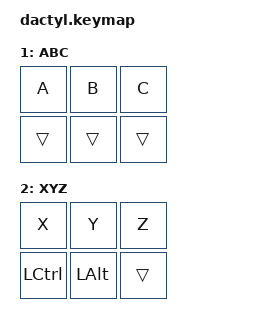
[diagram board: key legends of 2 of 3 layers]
#include <behaviors.dtsi>
#include <dt-bindings/zmk/keys.h>

/ {
       keymap {
        compatible = "zmk,keymap";
		
		
		default_layer { // Layer 0
            display-name = "Base";
// ----------------------------------------------
// |  Q  |   W   |   E   |  R   |  T   |                 
// |  A  |   S   |   D   |  F   |  G   |                 
// |  Z  |   X   |   C   |  V   |  B   |                  
//       |  ALT  |  GUI  |  1   |  2   |3  |  4  |			
//                                     |  5  |  6  | 
            bindings = <
                &kp Q   &kp W   &kp E   &kp R   &kp T  
                &kp A   &kp S   &kp D   &kp F   &kp G  
                &kp Z   &kp X   &kp C   &kp V   &kp B 
                        &kp ALT	&kp GUI	&kp 1   &kp 2   &kp 3   &kp 4
                                                        &kp 5   &kp 6
            >;
        };
		
		
        abc { // Layer 1
            display-name = "ABC";	
// ----------------------------------------------
// |      A      |       B       |       C      |
// |    &trans   |    &trans     |     &trans   |
            bindings = <
                &kp A     &kp B     &kp C
                &trans    &trans    &trans
            >;
        };
		
		
        xyz { // Layer 2
            display-name = "XYZ";	
// ----------------------------------------------
// |        X       |      Y       |      Z     |
// |   LEFT CTRL    |  LEFT ALT    |   &trans   |
            bindings = <
                &kp X        &kp Y       &kp Z
                &kp LCTRL    &kp LALT    &trans
            >;
    };
};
